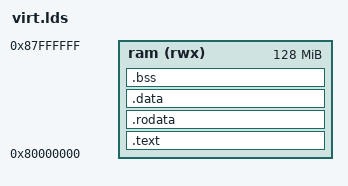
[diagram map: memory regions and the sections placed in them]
OUTPUT_ARCH(riscv)

ENTRY(_start)

MEMORY
{
    ram (rwx) : ORIGIN = 0x80000000, LENGTH = 128M
}

SECTIONS
{
    .text : {
        PROVIDE(_text_start = .);
        *(.text.init) *(.text .text.*)
        PROVIDE(_text_end = .);
    } >ram

    PROVIDE(_global_pointer = .);

    .rodata : {
        PROVIDE(_rodata_start = .);
        *(.rodata .rodata.*)
        PROVIDE(_rodata_end = .);
    } >ram

    .data : {
        . = ALIGN(4096);
        PROVIDE(_data_start = .);
        *(.sdata .sdata.*) *(.data .data.*)
        PROVIDE(_data_end = .);
    } >ram

    .bss : {
        PROVIDE(_bss_start = .);
        *(.sbss .sbss.*) *(.bss .bss.*)
        PROVIDE(_bss_end = .);
    } >ram

    PROVIDE(_memory_start = ORIGIN(ram));
    PROVIDE(_stack = _bss_end + 0x80000);
    PROVIDE(_memory_end = ORIGIN(ram) + LENGTH(ram));
    PROVIDE(_heap_start = _stack);
    PROVIDE(_heap_end = _memory_end);
}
